# ESP32-P4 register map
Vendor: ESPRESSIF SYSTEMS (SHANGHAI) CO., LTD.; Series: ESP32 P-Series; File version: 3
CPU: RV32IMAFC r0p0, little endian, no MPU, FPU, 0 interrupt priority bits
Address unit: 32 bits
Registers are 32-bit, read-write, reset 0x0 unless marked. A register's access mark holds for its fields unless they carry their own. Offsets are from the block's base; [hi:lo] are bit positions; {n}, {i} and the like mark numbered series.

## LP_GPIO — Low-power General Purpose Input/Output
Base 0x5012A000
0x00 CLK_EN reset 0x1 — Reserved
  [0] REG_CLK_EN
0x04 VER_DATE reset 0x230323 — Reserved
  [27:0] REG_VER_DATE
0x08 OUT — Reserved
  [15:0] REG_GPIO_OUT_DATA
0x0C OUT_W1TS wo — Reserved
  [15:0] REG_GPIO_OUT_DATA_W1TS
0x10 OUT_W1TC wo — Reserved
  [15:0] REG_GPIO_OUT_DATA_W1TC
0x14 ENABLE — Reserved
  [15:0] REG_GPIO_ENABLE_DATA
0x18 ENABLE_W1TS wo — Reserved
  [15:0] REG_GPIO_ENABLE_DATA_W1TS
0x1C ENABLE_W1TC wo — Reserved
  [15:0] REG_GPIO_ENABLE_DATA_W1TC
0x20 STATUS — Reserved
  [15:0] REG_GPIO_STATUS_DATA
0x24 STATUS_W1TS wo — Reserved
  [15:0] REG_GPIO_STATUS_DATA_W1TS
0x28 STATUS_W1TC wo — Reserved
  [15:0] REG_GPIO_STATUS_DATA_W1TC
0x2C STATUS_NEXT ro — Reserved
  [15:0] REG_GPIO_STATUS_INTERRUPT_NEXT
0x30 IN ro — Reserved
  [15:0] REG_GPIO_IN_DATA_NEXT
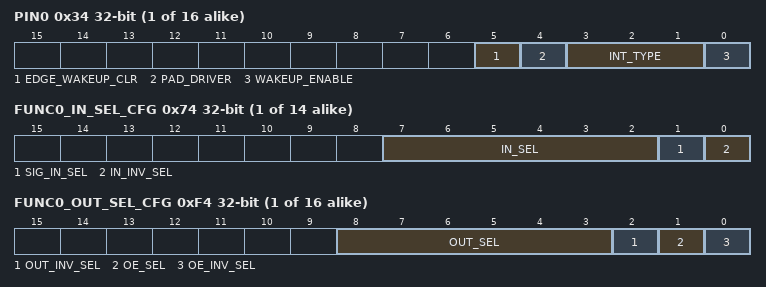
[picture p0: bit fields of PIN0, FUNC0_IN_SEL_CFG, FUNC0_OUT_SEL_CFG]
{0x34+4i} PIN{i} (i=0..15) — LP GPIO pin configuration register
  [5] EDGE_WAKEUP_CLR wo — need des
  [4] PAD_DRIVER — Reserved
  [3:1] INT_TYPE — Reserved
  [0] WAKEUP_ENABLE — Reserved
{0x74+4i} FUNC{i}_IN_SEL_CFG (i=0..13) — LP GPIO input function configuration register
  [7:2] IN_SEL — reg_gpio_func_in_sel[5:4]==2'b11->constant 1,reg_gpio_func_in_sel[5:4]==2'b10->constant 0
  [1] SIG_IN_SEL — Reserved
  [0] IN_INV_SEL — Reserved
{0xF4+4i} FUNC{i}_OUT_SEL_CFG (i=0..15) — LP GPIO output function configuration register
  [8:3] OUT_SEL — reg_gpio_func_out_sel[5:1]==16 -> output gpio register value to pad
  [2] OUT_INV_SEL — Reserved
  [1] OE_SEL — Reserved
  [0] OE_INV_SEL — Reserved

## LP_TRNG
Base 0x50126000
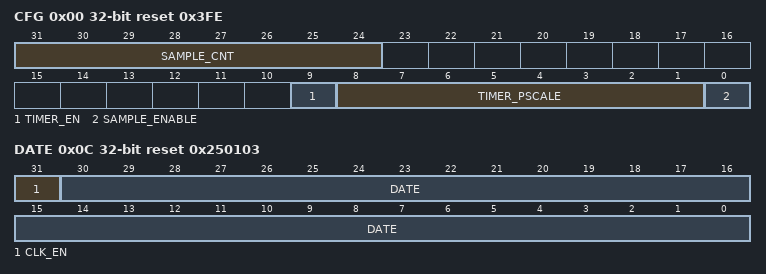
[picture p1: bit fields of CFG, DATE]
0x00 CFG access per field reset 0x3FE — configure rng register
  [31:24] SAMPLE_CNT ro — get rng RO sample cnt
  [9] TIMER_EN rw — enable rng xor async rng timer
  [8:1] TIMER_PSCALE rw — configure rng timer clk div
  [0] SAMPLE_ENABLE rw — enable rng RO
0x04 DATA ro — RNG result register
  [31:0] DATA — get rng data
0x08 RSTN reset 0x1 — rng rstn register
  [0] RSTN — enable rng system reset: 1: not reset, 0: reset
0x0C DATE reset 0x250103
  [31] CLK_EN, [30:0] DATE

## LP_IO_MUX — Low-power Input/Output Multiplexer
Base 0x5012B000
0x00 CLK_EN reset 0x1 — Reserved
  [0] REG_CLK_EN
0x04 VER_DATE reset 0x230313 — Reserved
  [27:0] REG_VER_DATE
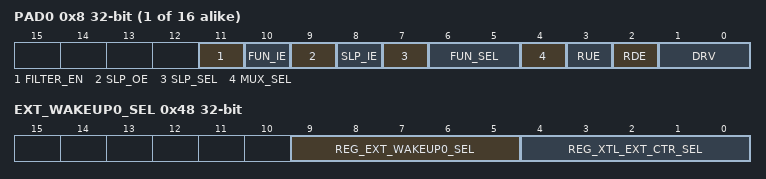
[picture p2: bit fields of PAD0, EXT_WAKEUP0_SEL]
{0x8+4i} PAD{i} (i=0..15) — LP IO MUX configuration register for pad {i}
  [11] FILTER_EN — need des
  [10] FUN_IE — input enable in work mode
  [9] SLP_OE — output enable in sleep mode
  [8] SLP_IE — input enable in sleep mode
  [7] SLP_SEL — 1: enable sleep mode during sleep,0: no sleep mode
  [6:5] FUN_SEL — function sel
  [4] MUX_SEL — 1:use LP GPIO,0: use digital GPIO
  [3] RUE — Reserved
  [2] RDE — Reserved
  [1:0] DRV — Reserved
0x48 EXT_WAKEUP0_SEL — Reserved
  [9:5] REG_EXT_WAKEUP0_SEL — Reserved
  [4:0] REG_XTL_EXT_CTR_SEL — select LP GPIO 0 ~ 15 to control XTAL
0x4C LP_PAD_HOLD — Reserved
  [15:0] REG_LP_GPIO_HOLD
0x50 LP_PAD_HYS — Reserved
  [15:0] REG_LP_GPIO_HYS

## PAU — PAU Peripheral
Base 0x50082000
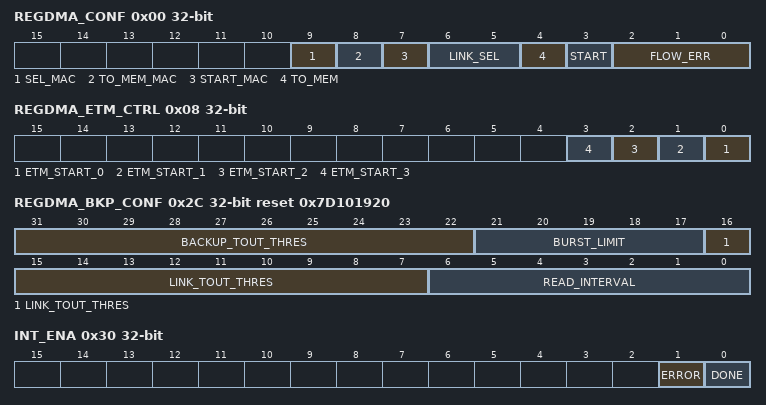
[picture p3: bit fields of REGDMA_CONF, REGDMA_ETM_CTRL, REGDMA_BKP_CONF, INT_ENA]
0x00 REGDMA_CONF access per field — Peri backup control register
  [9] SEL_MAC rw — mac hw/sw select
  [8] TO_MEM_MAC rw — mac sw backup direction(reg to mem / mem to reg)
  [7] START_MAC wo — mac sw backup start signal
  [6:5] LINK_SEL rw — Link select
  [4] TO_MEM rw — backup direction(reg to mem / mem to reg)
  [3] START wo — backup start signal
  [2:0] FLOW_ERR ro — backup error type
0x04 REGDMA_CLK_CONF — Clock control register
  [0] CLK_EN — clock enable
0x08 REGDMA_ETM_CTRL wo — ETM start ctrl reg
  [n] ETM_START_{n} (n=0..3) — etm_start_{n} reg
0x0C REGDMA_LINK_0_ADDR — link_0_addr
  [31:0] LINK_ADDR_0 — link_0_addr reg
{0xC+4i} REGDMA_LINK_{i}_ADDR (i=1..3) — Link_{i}_addr
  [31:0] LINK_ADDR_{i} — Link_{i}_addr reg
0x1C REGDMA_LINK_MAC_ADDR — Link_mac_addr
  [31:0] LINK_ADDR_MAC — Link_mac_addr reg
0x20 REGDMA_CURRENT_LINK_ADDR ro — current link addr
  [31:0] CURRENT_LINK_ADDR — current link addr reg
0x24 REGDMA_BACKUP_ADDR ro — Backup addr
  [31:0] BACKUP_ADDR — backup addr reg
0x28 REGDMA_MEM_ADDR ro — mem addr
  [31:0] MEM_ADDR — mem addr reg
0x2C REGDMA_BKP_CONF reset 0x7D101920 — backup config
  [31:22] BACKUP_TOUT_THRES — Backup timeout threshold
  [21:17] BURST_LIMIT
  [16:7] LINK_TOUT_THRES — link wait timeout threshold
  [6:0] READ_INTERVAL — Link read_interval
0x30 INT_ENA — Read only register for error and done
  [1] ERROR — error flag
  [0] DONE — backup done flag
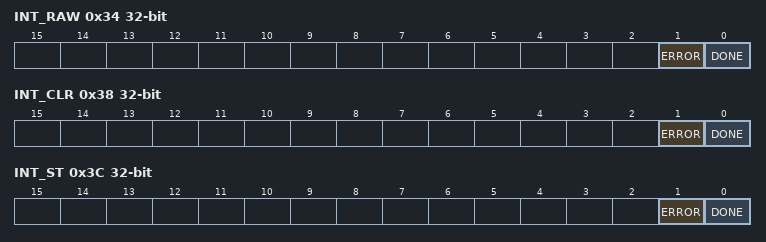
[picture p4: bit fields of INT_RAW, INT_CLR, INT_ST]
0x34 INT_RAW — Read only register for error and done
  [1] ERROR — error flag
  [0] DONE — backup done flag
0x38 INT_CLR wo — Read only register for error and done
  [1] ERROR write-1-clears — error flag
  [0] DONE write-1-clears — backup done flag
0x3C INT_ST ro — Read only register for error and done
  [1] ERROR — error flag
  [0] DONE — backup done flag
0x3FC DATE reset 0x2301310
  [27:0] DATE — REGDMA date information/ REGDMA version information.
